AUTOSAR XML (schema 00049)
package /SwComponentTypes
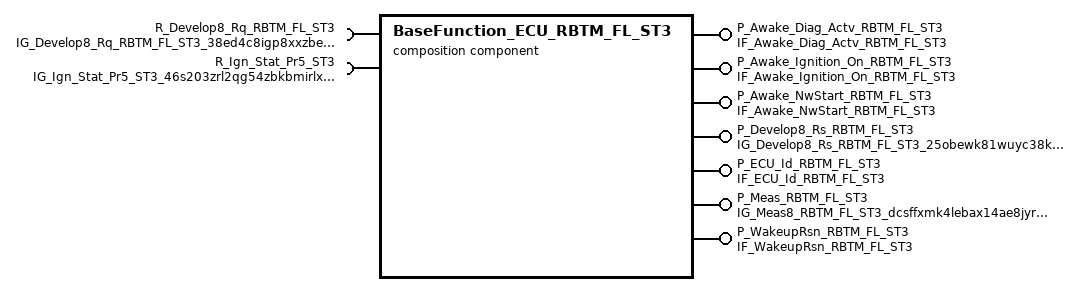
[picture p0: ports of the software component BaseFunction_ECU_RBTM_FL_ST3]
  composition sw component type BaseFunction_ECU_RBTM_FL_ST3  # Base Function
    7 x provide port:
      P_Awake_Diag_Actv_RBTM_FL_ST3: nonqueued-sender-com-spec{data-element=Awake_Diag_Actv_RBTM_FL_ST3, init-value=constant-reference=XDIS_h5tcyk98kzbgrc5svasomeyt}, provided-interface=IF_Awake_Diag_Actv_RBTM_FL_ST3  # Wachhalten für Diagnose aktiv / Stay awake for diagnostics active
      P_Awake_Ignition_On_RBTM_FL_ST3: nonqueued-sender-com-spec{data-element=Awake_Ignition_On_RBTM_FL_ST3, init-value=constant-reference=XDIS_h5tcyk98kzbgrc5svasomeyt}, provided-interface=IF_Awake_Ignition_On_RBTM_FL_ST3  # Wachhalten für Zündung eingeschaltet / Stay awake for ignition on
      P_Awake_NwStart_RBTM_FL_ST3: nonqueued-sender-com-spec{data-element=Awake_NwStart_RBTM_FL_ST3, init-value=constant-reference=XDIS_h5tcyk98kzbgrc5svasomeyt}, provided-interface=IF_Awake_NwStart_RBTM_FL_ST3  # Wachhalten für Netzwerkstartphase / Stay awake for network startup
      P_Develop8_Rs_RBTM_FL_ST3: nonqueued-sender-com-spec{data-element=Develop8_Rs_RBTM_FL_ST3, init-value=constant-reference=XDIS_dx2vtxvh1csnm7x2o8c32o294}, provided-interface=IG_Develop8_Rs_RBTM_FL_ST3_25obewk81wuyc38kk70ol6f0x  # Development Response (degraded)
      P_ECU_Id_RBTM_FL_ST3: nonqueued-sender-com-spec{data-element=ECU_Id_RBTM_FL_ST3, init-value=constant-reference=XDIS_69x5rmbg27ofsxv5i93olbdcr}, provided-interface=IF_ECU_Id_RBTM_FL_ST3  # ECU-Identifizierungsnummer / ECU identifier
      P_Meas_RBTM_FL_ST3: nonqueued-sender-com-spec{data-element=Meas8_RBTM_FL_ST3, init-value=constant-reference=XDIS_ckvw3q385offj9s5jhb6jp6cr}, provided-interface=IG_Meas8_RBTM_FL_ST3_dcsffxmk4lebax14ae8jyr2nd  # Messbotschaft (degraded) / Measurement (degraded)
      P_WakeupRsn_RBTM_FL_ST3: nonqueued-sender-com-spec{data-element=WakeupRsn_RBTM_FL_ST3, init-value=constant-reference=XDIS_3jaoqj7gfnekl0vo7yq70x2ub}, provided-interface=IF_WakeupRsn_RBTM_FL_ST3  # Weckgrund / Wakeup reason
    require port R_Develop8_Rq_RBTM_FL_ST3: nonqueued-receiver-com-spec{data-element=Develop8_Rq_RBTM_FL_ST3, reception-props=timeout=0, init-value=constant-reference=XDIS_1uf4istgprs3hvvzjvjv3yns0}, required-interface=IG_Develop8_Rq_RBTM_FL_ST3_38ed4c8igp8xxzbei3a6bgrm1  # Development Request (degraded)
    require port R_Ign_Stat_Pr5_ST3: nonqueued-receiver-com-spec=data-element=Ign_Stat_Pr5_ST3, required-interface=IG_Ign_Stat_Pr5_ST3_46s203zrl2qg54zbkbmirlx2b
    component BaseFunction: type=BaseFunction
    component Cdd_MBBL_EcuStatHandler: type=Cdd_MBBL_EcuStatHandler
    delegate BaseFunction.P_Awake_Diag_Actv_RBTM_FL_ST3 <-> outer port P_Awake_Diag_Actv_RBTM_FL_ST3
    delegate BaseFunction.P_Awake_Ignition_On_RBTM_FL_ST3 <-> outer port P_Awake_Ignition_On_RBTM_FL_ST3
    delegate BaseFunction.P_ECU_Id_RBTM_FL_ST3 <-> outer port P_ECU_Id_RBTM_FL_ST3
    delegate BaseFunction.P_Awake_NwStart_RBTM_FL_ST3 <-> outer port P_Awake_NwStart_RBTM_FL_ST3
    delegate BaseFunction.P_WakeupRsn_RBTM_FL_ST3 <-> outer port P_WakeupRsn_RBTM_FL_ST3
    delegate Cdd_MBBL_EcuStatHandler.Pp_Awake_Diag_Actv <-> outer port P_Awake_Diag_Actv_RBTM_FL_ST3
    delegate Cdd_MBBL_EcuStatHandler.Pp_Awake_Ignition_On <-> outer port P_Awake_Ignition_On_RBTM_FL_ST3
    delegate Cdd_MBBL_EcuStatHandler.Pp_Awake_NwStart_Cluster <-> outer port P_Awake_NwStart_RBTM_FL_ST3
    delegate Cdd_MBBL_EcuStatHandler.Pp_WakeupRsn <-> outer port P_WakeupRsn_RBTM_FL_ST3
    delegate Cdd_MBBL_EcuStatHandler.Pp_Ign_Stat <-> outer port R_Ign_Stat_Pr5_ST3
